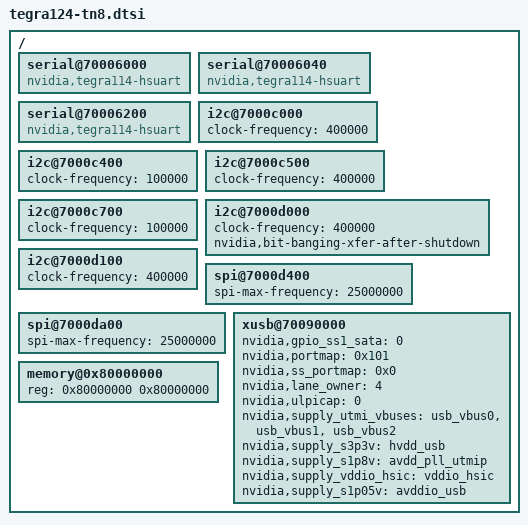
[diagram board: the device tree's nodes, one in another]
#include "tegra124.dtsi"

/ {
	serial@70006000 {
		compatible = "nvidia,tegra114-hsuart";
		status = "okay";
	};

	serial@70006040 {
		compatible = "nvidia,tegra114-hsuart";
		status = "okay";
	};

	serial@70006200 {
		compatible = "nvidia,tegra114-hsuart";
		status = "okay";
	};

	i2c@7000c000 {
		status = "okay";
		clock-frequency = <400000>;
	};

	i2c@7000c400 {
		status = "okay";
		clock-frequency = <100000>;
	};

	i2c@7000c500 {
		status = "okay";
		clock-frequency = <400000>;
	};

	i2c@7000c700 {
		status = "okay";
		clock-frequency = <100000>;
	};

	i2c@7000d000 {
		status = "okay";
		clock-frequency = <400000>;
		nvidia,bit-banging-xfer-after-shutdown;
	};

	i2c@7000d100 {
		status = "okay";
		clock-frequency = <400000>;
	};

	spi@7000d400 {
		status = "okay";
		spi-max-frequency = <25000000>;
	};

	spi@7000da00 {
		status = "okay";
		spi-max-frequency = <25000000>;
	};

	xusb@70090000 {
		/* nvidia,uses_external_pmic;
		nvidia,gpio_controls_muxed_ss_lanes; */
		nvidia,gpio_ss1_sata = <0>;
		nvidia,portmap = <0x101>; /* SSP0, USB2P0 */
		nvidia,ss_portmap = <0x0>; /* SSP0 on USB2P0 */
		nvidia,lane_owner = <4>; /* USB3P0 */
		nvidia,ulpicap = <0>; /* No ulpi support. can we remove */
		nvidia,supply_utmi_vbuses = "usb_vbus0", "usb_vbus1", "usb_vbus2";
		nvidia,supply_s3p3v = "hvdd_usb";
		nvidia,supply_s1p8v = "avdd_pll_utmip";
		nvidia,supply_vddio_hsic = "vddio_hsic";
		nvidia,supply_s1p05v = "avddio_usb";
		status = "okay";
	};

	memory@0x80000000 {
		device_type = "memory";
		reg = <0x80000000 0x80000000>;
	};
};
